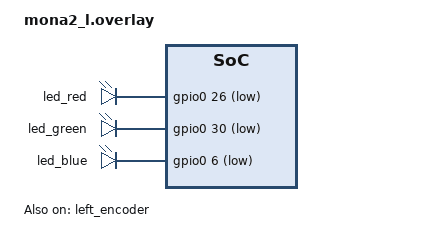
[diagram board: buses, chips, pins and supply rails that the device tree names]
#include "mona2.dtsi"

&kscan0 {
        col-gpios
            = <&xiao_d 10 GPIO_ACTIVE_HIGH>
            , <&xiao_d 9 GPIO_ACTIVE_HIGH> 
            , <&xiao_d 8 GPIO_ACTIVE_HIGH> 
            , <&xiao_d 7 GPIO_ACTIVE_HIGH> 
            , <&gpio0 10 GPIO_ACTIVE_HIGH>
            , <&gpio0 9 GPIO_ACTIVE_HIGH>
            ;
};

&left_encoder {
    status = "okay";
};


/ {
        aliases {
        　led-red = &led_red;
        　led-green = &led_green;
        　led-blue = &led_blue;
        };

        leds {
        　compatible = "gpio-leds";
        　led_red: led_red {
                gpios = <&gpio0 26 GPIO_ACTIVE_LOW>; /* ← 要確認 */
        　};
        　led_green: led_green {
                gpios = <&gpio0 30 GPIO_ACTIVE_LOW>; /* ← 要確認 */
        　};
        　led_blue: led_blue {
                gpios = <&gpio0 6 GPIO_ACTIVE_LOW>; /* ← 要確認 */
        　};
　　};
};
